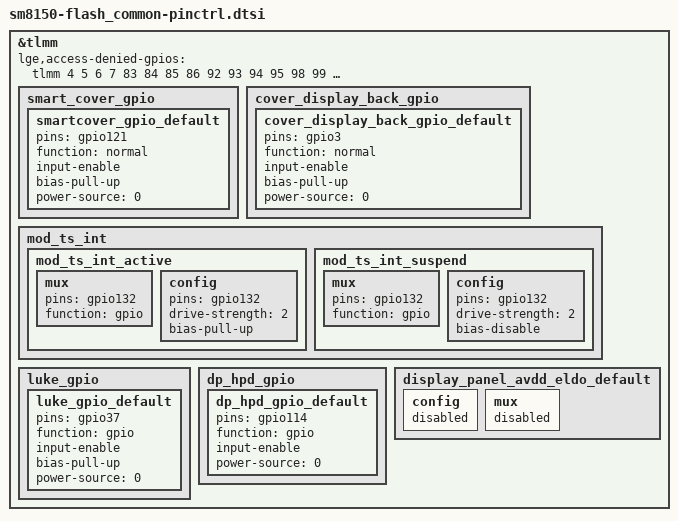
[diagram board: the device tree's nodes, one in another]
/*
 * Copyright (c) 2018, The Linux Foundation. All rights reserved.
 *
 * This program is free software; you can redistribute it and/or modify
 * it under the terms of the GNU General Public License version 2 and
 * only version 2 as published by the Free Software Foundation.
 *
 * This program is distributed in the hope that it will be useful,
 * but WITHOUT ANY WARRANTY; without even the implied warranty of
 * MERCHANTABILITY or FITNESS FOR A PARTICULAR PURPOSE.  See the
 * GNU General Public License for more details.
 */

#include "../../sm8150_common/sm8150_common-pinctrl.dtsi"

&tlmm {
	lge,access-denied-gpios = <&tlmm 4 5 6 7 83 84 85 86 92 93 94 95 98 99 100 101>;

	smart_cover_gpio {
		 smartcover_gpio_default: smartcover_gpio_default {
			pins = "gpio121";
			function = "normal";
			input-enable;
			bias-pull-up;
			power-source = <0>;
			};
	};
	cover_display_back_gpio {
		 cover_display_back_gpio_default: cover_display_back_gpio_default {
			pins = "gpio3";
			function = "normal";
			input-enable;
			bias-pull-up;
			power-source = <0>;
			};
	};

	/* pin ctrl for Touch module */
	mod_ts_int {
		mod_ts_int_active: mod_ts_int_active {
			mux {
				pins = "gpio132";
				function = "gpio";
			};
			config {
				pins = "gpio132";
				drive-strength = <2>;
				bias-pull-up;
			};
		};

		mod_ts_int_suspend: mod_ts_int_suspend {
			mux {
				pins = "gpio132";
				function = "gpio";
			};
			config {
				pins = "gpio132";
				drive-strength = <2>;
				bias-disable;
			};
		};
	};

	/* pin set for LUKE */
	luke_gpio {
		luke_gpio_default: luke_gpio_default {
			pins = "gpio37";
			function = "gpio";
			input-enable;
			bias-pull-up;
			power-source = <0>;
		};
	};

	/* pin set for DP_HPD */
	dp_hpd_gpio {
		dp_hpd_gpio_default: dp_hpd_gpio_default {
			pins = "gpio114";
			function = "gpio";
			input-enable;
			power-source = <0>;
		};
	};

	display_panel_avdd_eldo_default {
		config {
			status = "disabled";
		};
		mux {
			status = "disabled";
		};
	};
};
